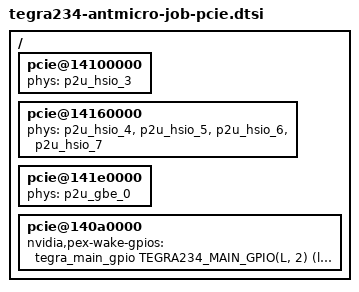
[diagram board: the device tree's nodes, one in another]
/*
 * Copyright (c) 2023 Antmicro <www.antmicro.com>
 *
 * This program is free software; you can redistribute it and/or modify
 * it under the terms of the GNU General Public License as published by
 * the Free Software Foundation; version 2 of the License.
 *
 * This program is distributed in the hope that it will be useful, but WITHOUT
 * ANY WARRANTY; without even the implied warranty of MERCHANTABILITY or
 * FITNESS FOR A PARTICULAR PURPOSE.  See the GNU General Public License for
 * more details.
 */


/*
 * PCIe definitions for Antmicro Jetson Orin Baseboard
 */

/ {
	pcie@14100000 {/* C1 - M.2 Key-E */
		status = "okay";
		phys = <&p2u_hsio_3>;
		phy-names = "p2u-0";
	};

	pcie@14160000 {/* C4 - M2 Key M */
		status = "okay";
		phys = <&p2u_hsio_4>, <&p2u_hsio_5>, <&p2u_hsio_6>,
		       <&p2u_hsio_7>;
		phy-names = "p2u-0", "p2u-1", "p2u-2", "p2u-3";
	};

	pcie@141e0000 {/* PCIe C7 - M.2 on JOB storage expansion board */
		status = "okay";
		phys = <&p2u_gbe_0>;
		phy-names = "p2u-0";
	};

	pcie@140a0000 {/* C8 - Ethernet */
		status = "okay";

		nvidia,pex-wake-gpios = <&tegra_main_gpio TEGRA234_MAIN_GPIO(L, 2) GPIO_ACTIVE_LOW>;
	};
};
